VERSION ""

NS_ :

BS_:

BU_:
VAL_TABLE_ status_cmd 1 "cmd disable" 0 "cmd enable" ;
VAL_TABLE_ direction_cmd 1 "backword" 0 "forward" ;

BO_ 2550202115 machine_state: 1 Vector__XXX
 SG_ alive_counter : 0|8@1+ (1,0) [0|0] "" Vector__XXX

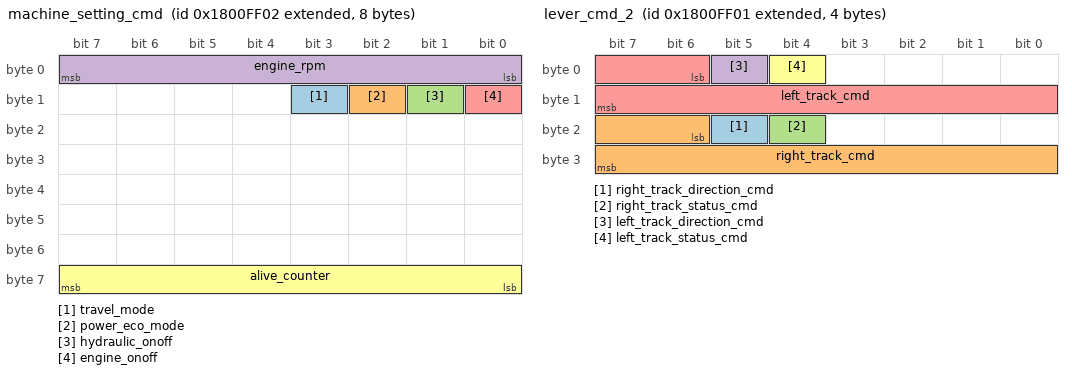
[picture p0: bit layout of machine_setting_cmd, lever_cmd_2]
BO_ 2550202114 machine_setting_cmd: 8 Vector__XXX
 SG_ travel_mode : 11|1@1+ (1,0) [0|0] "" Vector__XXX
 SG_ power_eco_mode : 10|1@1+ (1,0) [0|0] "" Vector__XXX
 SG_ hydraulic_onoff : 9|1@1+ (1,0) [0|0] "" Vector__XXX
 SG_ engine_rpm : 0|8@1+ (1,0) [0|0] "%" Vector__XXX
 SG_ engine_onoff : 8|1@1+ (1,0) [0|0] "" Vector__XXX
 SG_ alive_counter : 56|8@1+ (1,0) [0|0] "" Vector__XXX

BO_ 2550202113 lever_cmd_2: 4 Vector__XXX
 SG_ right_track_direction_cmd : 21|1@1+ (1,0) [0|0] "" Vector__XXX
 SG_ right_track_cmd : 22|10@1+ (0.1,0) [0|102.3] "%" Vector__XXX
 SG_ right_track_status_cmd : 20|1@1+ (1,0) [0|0] "" Vector__XXX
 SG_ left_track_direction_cmd : 5|1@1+ (1,0) [0|0] "" Vector__XXX
 SG_ left_track_cmd : 6|10@1+ (0.1,0) [0|102.3] "%" Vector__XXX
 SG_ left_track_status_cmd : 4|1@1+ (1,0) [0|0] "" Vector__XXX

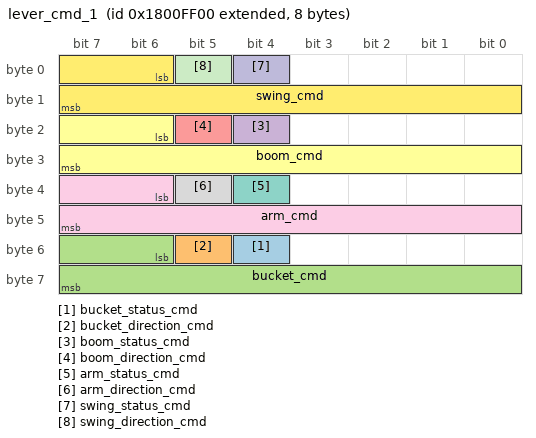
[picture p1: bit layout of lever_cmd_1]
BO_ 2550202112 lever_cmd_1: 8 Vector__XXX
 SG_ bucket_status_cmd : 52|1@1+ (1,0) [0|0] "" Vector__XXX
 SG_ bucket_direction_cmd : 53|1@1+ (1,0) [0|0] "" Vector__XXX
 SG_ bucket_cmd : 54|10@1+ (0.1,0) [0|102.3] "%" Vector__XXX
 SG_ boom_status_cmd : 20|1@1+ (1,0) [0|0] "" Vector__XXX
 SG_ boom_direction_cmd : 21|1@1+ (1,0) [0|0] "" Vector__XXX
 SG_ boom_cmd : 22|10@1+ (0.1,0) [0|102.3] "%" Vector__XXX
 SG_ arm_status_cmd : 36|1@1+ (1,0) [0|0] "" Vector__XXX
 SG_ arm_direction_cmd : 37|1@1+ (1,0) [0|0] "" Vector__XXX
 SG_ arm_cmd : 38|10@1+ (0.1,0) [0|102.3] "%" Vector__XXX
 SG_ swing_status_cmd : 4|1@1+ (1,0) [0|0] "" Vector__XXX
 SG_ swing_direction_cmd : 5|1@1+ (1,0) [0|0] "" Vector__XXX
 SG_ swing_cmd : 6|10@1+ (0.1,0) [0|102.3] "%" Vector__XXX

BA_DEF_ BO_  "GenMsgCycleTime" INT 0 3600000;
BA_DEF_  "DBName" STRING ;
BA_DEF_ BO_  "VFrameFormat" ENUM  "StandardCAN","ExtendedCAN","reserved","J1939PG";
BA_DEF_DEF_  "GenMsgCycleTime" 0;
BA_DEF_DEF_  "DBName" "";
BA_DEF_DEF_  "VFrameFormat" "J1939PG";
BA_ "DBName" "excavator_com3";
BA_ "GenMsgCycleTime" BO_ 2550202115 100;
BA_ "VFrameFormat" BO_ 2550202115 1;
BA_ "GenMsgCycleTime" BO_ 2550202114 100;
BA_ "VFrameFormat" BO_ 2550202114 1;
BA_ "VFrameFormat" BO_ 2550202113 1;
BA_ "GenMsgCycleTime" BO_ 2550202113 10;
BA_ "VFrameFormat" BO_ 2550202112 1;
BA_ "GenMsgCycleTime" BO_ 2550202112 10;
VAL_ 2550202113 right_track_direction_cmd 1 "backword" 0 "forward" ;
VAL_ 2550202113 right_track_status_cmd 1 "cmd disable" 0 "cmd enable" ;
VAL_ 2550202113 left_track_direction_cmd 1 "backword" 0 "forward" ;
VAL_ 2550202113 left_track_status_cmd 1 "cmd disable" 0 "cmd enable" ;
VAL_ 2550202112 bucket_status_cmd 1 "cmd disable" 0 "cmd enable" ;
VAL_ 2550202112 bucket_direction_cmd 1 "backword" 0 "forward" ;
VAL_ 2550202112 boom_status_cmd 1 "cmd disable" 0 "cmd enable" ;
VAL_ 2550202112 boom_direction_cmd 1 "backword" 0 "forward" ;
VAL_ 2550202112 arm_status_cmd 1 "cmd disable" 0 "cmd enable" ;
VAL_ 2550202112 arm_direction_cmd 1 "backword" 0 "forward" ;
VAL_ 2550202112 swing_status_cmd 1 "cmd disable" 0 "cmd enable" ;
VAL_ 2550202112 swing_direction_cmd 1 "backword" 0 "forward" ;
